# Z32F1281 register map
Vendor: Zilog, Inc; File version: 1.0
CPU: CM3 r1p0, little endian, no MPU, no FPU, 3 interrupt priority bits
Registers are 32-bit, read-write, reset 0x0 unless marked. A register's access mark holds for its fields unless they carry their own. Offsets are from the block's base; [hi:lo] are bit positions; {n}, {i} and the like mark numbered series; 'fields as' and 'values as' point back to an identical list.

## SCU — SYSTEM CONTROL UNIT
Base 0x40000000
0x00 CIDR ro reset 0xAC338128 — Chip ID Register
0x04 SMR — System Mode Register
  [5:4] PREVMODE
0x08 SRCR — System Reset Control Register
  [0] SWRST — Internal soft reset activation
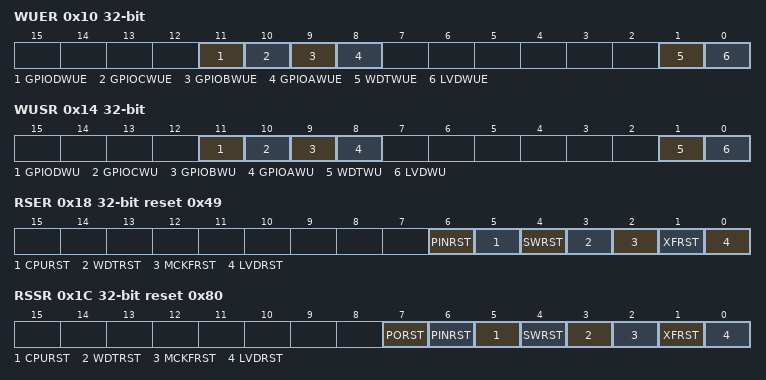
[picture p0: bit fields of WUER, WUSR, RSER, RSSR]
0x10 WUER — Wakeup Source Enable Register
  [11] GPIODWUE, [10] GPIOCWUE, [9] GPIOBWUE, [8] GPIOAWUE, [1] WDTWUE, [0] LVDWUE
0x14 WUSR ro — Wakeup Source Status Register
  [11] GPIODWU, [10] GPIOCWU, [9] GPIOBWU, [8] GPIOAWU, [1] WDTWU, [0] LVDWU
0x18 RSER reset 0x49 — Reset Source Enable Register
  [6] PINRST — external pin reset enable
  [5] CPURST — CPU request reset enable
  [4] SWRST — software reset enable
  [3] WDTRST — watch dog reset enable
  [2] MCKFRST — MCLK failed reset enable
  [1] XFRST — external OSC clock failed enable
  [0] LVDRST — LVD reset enable
0x1C RSSR reset 0x80 — Reset Source Status Register
  [7] PORST — power on reset status
  [6] PINRST — extenral pin reset status
  [5] CPURST — cpu request reset status
  [4] SWRST — software reset status
  [3] WDTRST — watchdog timer reset status
  [2] MCKFRST — MCLK failed reset status
  [1] XFRST — clock failed reset status
  [0] LVDRST — lvd reset status
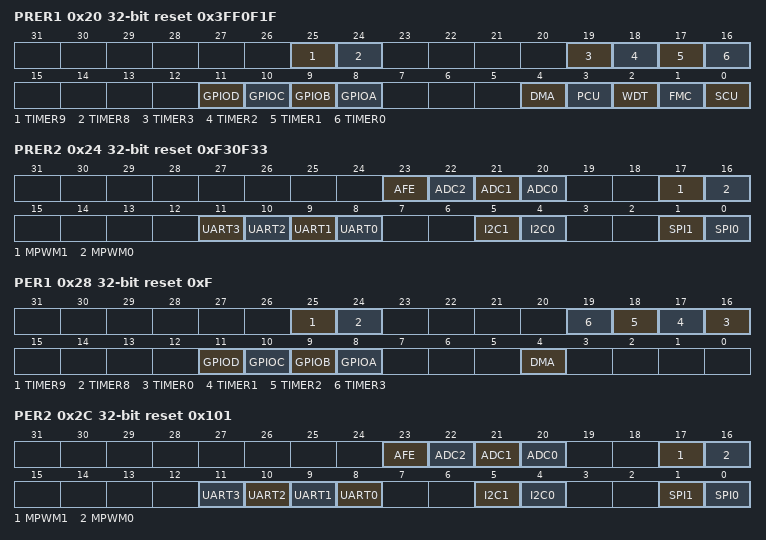
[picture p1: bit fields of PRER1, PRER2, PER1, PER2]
0x20 PRER1 reset 0x3FF0F1F — Peripheral Reset Enable Register 1
  [25] TIMER9 — TIMER9 Reset
  [24] TIMER8 — TIMER8 Reset
  [19] TIMER3 — TIMER3 Reset
  [18] TIMER2 — TIMER2 Reset
  [17] TIMER1 — TIMER1 Reset
  [16] TIMER0 — TIMER0 reset
  [11] GPIOD — GPIOD Reset
  [10] GPIOC — GPIOC Reset
  [9] GPIOB — GPIOB Reset
  [8] GPIOA — GPIOA Reset
  [4] DMA — DMA Reset
  [3] PCU — Port controll Reset
  [2] WDT — Watch Dog Timer Reset
  [1] FMC — Flash Memory controll Reset
  [0] SCU — Power Management Unit Reset
0x24 PRER2 reset 0xF30F33 — Peripheral Reset Enable Register 2
  [23] AFE — AFE Reset
  [22] ADC2 — ADC2 Reset
  [21] ADC1 — ADC1 Reset
  [20] ADC0 — ADC0 Reset
  [17] MPWM1 — MPWM1 Reset
  [16] MPWM0 — MPWM0 Reset
  [11] UART3
  [10] UART2
  [9] UART1
  [8] UART0 — UART0 Reset
  [5] I2C1 — I2C1 Reset
  [4] I2C0 — I2C0 Reset
  [1] SPI1 — SPI1 Reset
  [0] SPI0 — SPI0 Reset
0x28 PER1 reset 0xF — Peripheral Enable Register 1
  [25] TIMER9 — TIMER9 Enable
  [24] TIMER8 — TIMER8 Enable
  [n+16] TIMER{n} (n=0..3)
  [11] GPIOD
  [10] GPIOC
  [9] GPIOB
  [8] GPIOA
  [4] DMA — DMA Function Enable
0x2C PER2 reset 0x101 — Peripheral Enable Register 2
  [23] AFE
  [22] ADC2
  [21] ADC1
  [20] ADC0
  [17] MPWM1 — MPWM1 Enable
  [16] MPWM0 — MPWM0 Enable
  [n+8] UART{n} (n=0..3) — UART{n} Enable
  [5] I2C1 — I2C1 Enable
  [4] I2C0 — I2C0 Enable
  [1] SPI1 — SPI1 Enable
  [0] SPI0 — SPI0 Enable
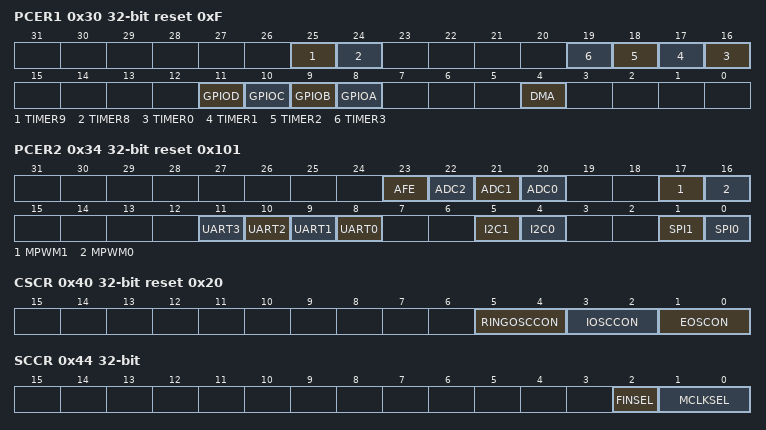
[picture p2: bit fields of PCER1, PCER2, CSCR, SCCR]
0x30 PCER1 reset 0xF — Peripheral Clock Enable Register 1
  fields as PER1
0x34 PCER2 reset 0x101 — Peripheral Clock Enable Register 2
  fields as PER2
0x40 CSCR reset 0x20 — Clock Source Control Register
  [5:4] RINGOSCCON — Internal ring OSC control
  [3:2] IOSCCON — Internal OSC control
  [1:0] EOSCON — External crystal OSC control
0x44 SCCR — System Clock Control Register
  [2] FINSEL — PLL Input source FIN Select
  [1:0] MCLKSEL — System clock select
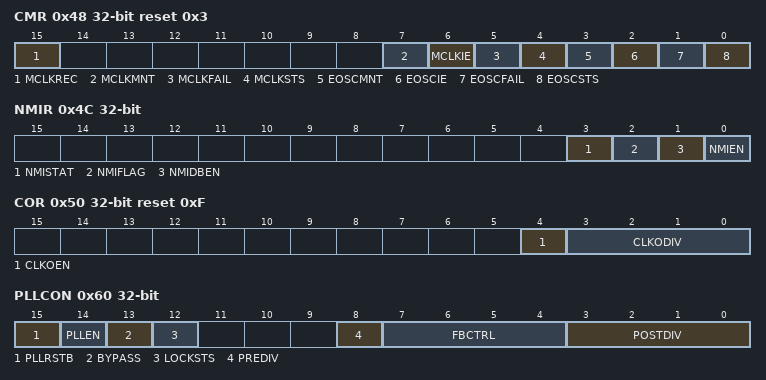
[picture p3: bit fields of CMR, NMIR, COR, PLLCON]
0x48 CMR reset 0x3 — Clock Monitoring Register
  [15] MCLKREC ro — MCLK failed auto recovery
  [7] MCLKMNT — MCLK monitor enable
  [6] MCLKIE — MCLK fail Interrupt enable
  [5] MCLKFAIL — MCLK Failed flag
  [4] MCLKSTS — MCLK clock status
  [3] EOSCMNT — Externaler OSC monitor enable
  [2] EOSCIE — external OSC failed interrupt enable
  [1] EOSCFAIL — external OSC failed flag
  [0] EOSCSTS — external OSC status
0x4C NMIR — NMI Control Register
  [3] NMISTAT — NMI Pin status
  [2] NMIFLAG — NMI interrupt flag
  [1] NMIDBEN — NMI Debounce enable
  [0] NMIEN
0x50 COR reset 0xF — Clock Output Register
  [4] CLKOEN — clock output enable
  [3:0] CLKODIV — clock output divider value
0x60 PLLCON — PLL Control Register
  [15] PLLRSTB — PLL reset
  [14] PLLEN — PLL Enable
  [13] BYPASS — FIN Bypass to FOUT
  [12] LOCKSTS ro — PLL Lock state
  [8] PREDIV — FIN pre divider
  [7:4] FBCTRL — Feedback control
  [3:0] POSTDIV — post divider
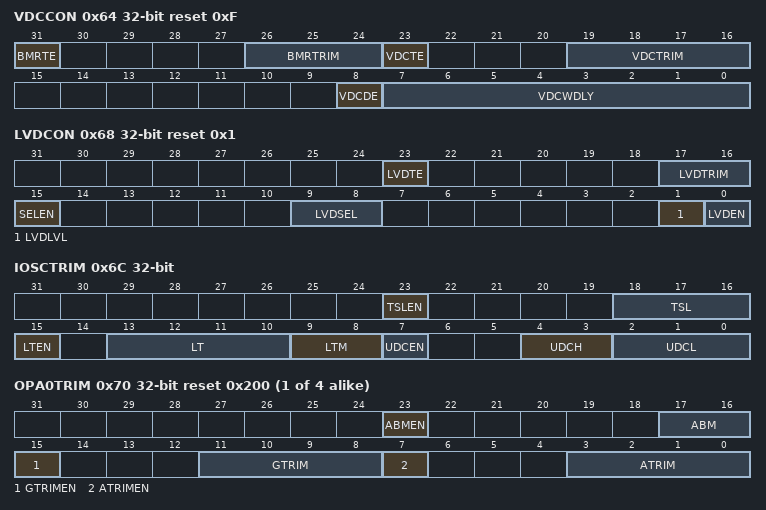
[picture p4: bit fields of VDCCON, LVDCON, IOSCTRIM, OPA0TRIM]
0x64 VDCCON reset 0xF — VDC Control Register
  [31] BMRTE wo — Reference BGR Trim write enable
  [26:24] BMRTRIM — Reference BGR output voltage trim value
  [23] VDCTE wo — VDCTRIM Value write enable
  [19:16] VDCTRIM — VDC output voltage trim value
  [8] VDCDE wo — VDC Warm-up Delay value write enable
  [7:0] VDCWDLY — VDC warm up delay count
0x68 LVDCON reset 0x1 — LVD Control Register
  [23] LVDTE wo — LVDTRIM value write enable
  [17:16] LVDTRIM — LVD voltage level trim value
  [15] SELEN wo — LVDSEL value write enable
  [9:8] LVDSEL — LVD detect level select
  [1] LVDLVL ro — LVD Level state
  [0] LVDEN — LVD function enable
0x6C IOSCTRIM — Internal OSC Trim Register
  [23] TSLEN
  [18:16] TSL
  [15] LTEN
  [13:10] LT — interal oscillator LT trim value
  [9:8] LTM — interal oscillator LT trim value
  [7] UDCEN
  [4:3] UDCH
  [2:0] UDCL
{0x70+4i} OPA{i}TRIM reset 0x200 (i=0..3) — Internal OPAMP {i} Trim Register
  [23] ABMEN wo — ABM trim value write enable
  [17:16] ABM — OPAMP BIAS trim value
  [15] GTRIMEN wo — GTRIM value write enable
  [11:8] GTRIM — Opamp Gain Trim value
  [7] ATRIMEN wo — ATRIM value write enable
  [3:0] ATRIM — OPAMP VIO (offset) Trim
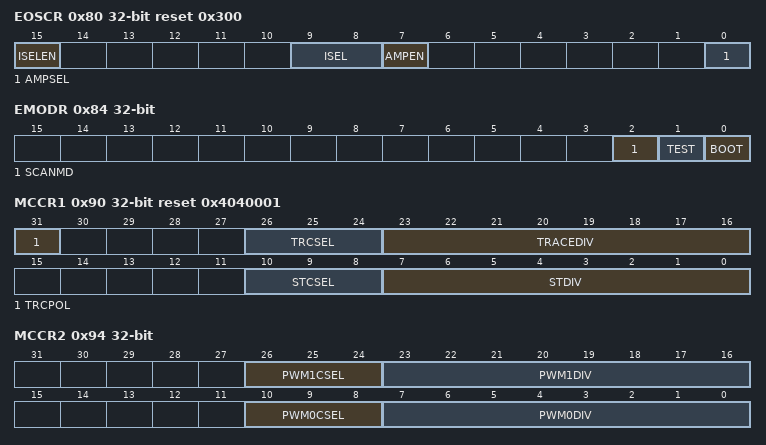
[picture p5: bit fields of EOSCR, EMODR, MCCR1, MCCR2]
0x80 EOSCR reset 0x300 — External Oscillator Control Register
  [15] ISELEN wo — write enable for bit field ISEL
  [9:8] ISEL — select current
  [7] AMPEN wo — write enable for bit field AMPSEL
  [0] AMPSEL — Select AMP type
0x84 EMODR — External Mode Status Register
  [2] SCANMD — scan mode pin level
  [1] TEST — TEST PIN level
  [0] BOOT — boot pin level
0x90 MCCR1 reset 0x4040001 — Miscellaneous Clock Control Register 1
  [31] TRCPOL wo
  [26:24] TRCSEL — trace clock source sel
  [23:16] TRACEDIV
  [10:8] STCSEL — systick clock source sel
  [7:0] STDIV — systick divider
0x94 MCCR2 — Miscellaneous Clock Control Register 2
  [26:24] PWM1CSEL — PWM1 clock sel
  [23:16] PWM1DIV — pwm1 divider
  [10:8] PWM0CSEL — pwm0 clock sel
  [7:0] PWM0DIV — PWM0 divider
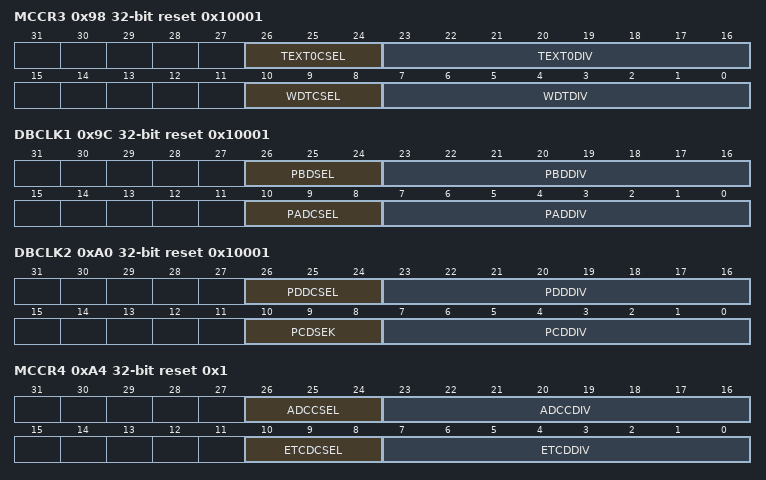
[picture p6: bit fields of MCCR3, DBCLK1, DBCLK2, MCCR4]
0x98 MCCR3 reset 0x10001 — Miscellaneous Clock Control Register 3
  [26:24] TEXT0CSEL — text0 clock sel
  [23:16] TEXT0DIV — text0 divider
  [10:8] WDTCSEL — WDT clock sel
  [7:0] WDTDIV — WDT divider
0x9C DBCLK1 reset 0x10001 — Debounce Clock Control Register 1
  [26:24] PBDSEL — debouce clock for port B source clock sel
  [23:16] PBDDIV — PORT B debounce divider
  [10:8] PADCSEL — debouce clock for port A source clock sel
  [7:0] PADDIV — PORT A debounce divider
0xA0 DBCLK2 reset 0x10001 — Debounce Clock Control Register 2
  [26:24] PDDCSEL — debouce clock for port D source clock sel
  [23:16] PDDDIV — PORT D debounce divider
  [10:8] PCDSEK — debouce clock for port C source clock sel
  [7:0] PCDDIV — PORT C debounce divider
0xA4 MCCR4 reset 0x1 — Miscellaneous Clock Control Register 4
  [26:24] ADCCSEL — ADC clock source select bitl
  [23:16] ADCCDIV — ADC Clock N divider
  [10:8] ETCDCSEL — Debouce clock for ETC source clock sel
  [7:0] ETCDDIV — ETC Debounce clock divider
